AUTOSAR XML (schema 00051)
package /ComponentTypes
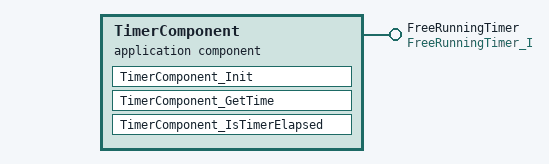
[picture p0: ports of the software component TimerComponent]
  application sw component type TimerComponent
    provide port FreeRunningTimer: provided-com-specs=[{operation=GetTime, queue-length=1}, {operation=IsTimerElapsed, queue-length=1}], provided-interface=FreeRunningTimer_I
    behavior TimerComponent_InternalBehavior
      init event IT_TimerComponent_Init: start-on-event=TimerComponent_Init
      operation invoked event OIT_TimerComponent_GetTime_FreeRunningTimer_GetTime: start-on-event=TimerComponent_GetTime, operation=FreeRunningTimer.GetTime
      operation invoked event OIT_TimerComponent_IsTimerElapsed_FreeRunningTimer_IsTimerElapsed: start-on-event=TimerComponent_IsTimerElapsed, operation=FreeRunningTimer.IsTimerElapsed
      runnable TimerComponent_Init
      runnable TimerComponent_GetTime: reentrancy-level=NON-REENTRANT
      runnable TimerComponent_IsTimerElapsed: reentrancy-level=NON-REENTRANT
  swc implementation TimerComponent_Implementation: behavior=TimerComponent_InternalBehavior
